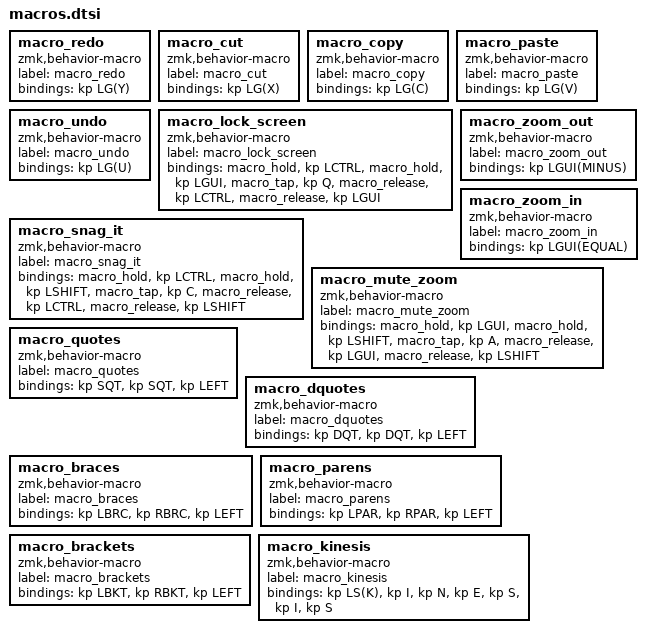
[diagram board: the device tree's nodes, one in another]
macro_redo: macro_redo{
compatible = "zmk,behavior-macro";
label = "macro_redo";
#binding-cells = <0>;
bindings = <&kp LG(Y)>;
};
macro_cut: macro_cut{
compatible = "zmk,behavior-macro";
label = "macro_cut";
#binding-cells = <0>;
bindings = <&kp LG(X)>;
};
macro_copy: macro_copy{
compatible = "zmk,behavior-macro";
label = "macro_copy";
#binding-cells = <0>;
bindings = <&kp LG(C)>;
};
macro_paste: macro_paste{
compatible = "zmk,behavior-macro";
label = "macro_paste";
#binding-cells = <0>;
bindings = <&kp LG(V)>;
};
macro_undo: macro_undo{
compatible = "zmk,behavior-macro";
label = "macro_undo";
#binding-cells = <0>;
bindings = <&kp LG(U)>;
};
macro_lock_screen: macro_lock_screen{
compatible = "zmk,behavior-macro";
label = "macro_lock_screen";
#binding-cells = <0>;
bindings = <&macro_hold &kp LCTRL>, <&macro_hold &kp LGUI>, <&macro_tap &kp Q>, <&macro_release &kp LCTRL>, <&macro_release &kp LGUI>;
};
macro_zoom_out: macro_zoom_out{
compatible = "zmk,behavior-macro";
label = "macro_zoom_out";
#binding-cells = <0>;
bindings = <&kp LGUI(MINUS)>;
};
macro_zoom_in: macro_zoom_in{
compatible = "zmk,behavior-macro";
label = "macro_zoom_in";
#binding-cells = <0>;
bindings = <&kp LGUI(EQUAL)>;
};
macro_snag_it: macro_snag_it{
compatible = "zmk,behavior-macro";
label = "macro_snag_it";
#binding-cells = <0>;
bindings = <&macro_hold &kp LCTRL>, <&macro_hold &kp LSHIFT>, <&macro_tap &kp C>, <&macro_release &kp LCTRL>, <&macro_release &kp LSHIFT>;
};
macro_mute_zoom: macro_mute_zoom{
compatible = "zmk,behavior-macro";
label = "macro_mute_zoom";
#binding-cells = <0>;
bindings = <&macro_hold &kp LGUI>, <&macro_hold &kp LSHIFT>, <&macro_tap &kp A>, <&macro_release &kp LGUI>, <&macro_release &kp LSHIFT>;
};
macro_quotes: macro_quotes{
compatible = "zmk,behavior-macro";
label = "macro_quotes";
#binding-cells = <0>;
bindings = <&kp SQT>, <&kp SQT>, <&kp LEFT>;
};
macro_dquotes: macro_dquotes{
compatible = "zmk,behavior-macro";
label = "macro_dquotes";
#binding-cells = <0>;
bindings = <&kp DQT>, <&kp DQT>, <&kp LEFT>;
};
macro_braces: macro_braces{
compatible = "zmk,behavior-macro";
label = "macro_braces";
#binding-cells = <0>;
bindings = <&kp LBRC>, <&kp RBRC>, <&kp LEFT>;
};
macro_parens: macro_parens{
compatible = "zmk,behavior-macro";
label = "macro_parens";
#binding-cells = <0>;
bindings = <&kp LPAR>, <&kp RPAR>, <&kp LEFT>;
};
macro_brackets: macro_brackets{
compatible = "zmk,behavior-macro";
label = "macro_brackets";
#binding-cells = <0>;
bindings = <&kp LBKT>, <&kp RBKT>, <&kp LEFT>;
};
macro_kinesis: macro_kinesis{
compatible = "zmk,behavior-macro";
label = "macro_kinesis";
#binding-cells = <0>;
bindings = <&kp LS(K)>, <&kp I>, <&kp N>, <&kp E>, <&kp S>, <&kp I>, <&kp S>;
};
